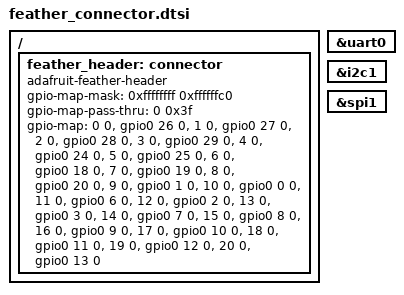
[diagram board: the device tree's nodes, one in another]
/*
 * Copyright (c) 2020 Richard Osterloh <richard.osterloh@gmail.com>
 *
 * SPDX-License-Identifier: Apache-2.0
 */

/ {
	feather_header: connector {
		compatible = "adafruit-feather-header";
		#gpio-cells = <2>;
		gpio-map-mask = <0xffffffff 0xffffffc0>;
		gpio-map-pass-thru = <0 0x3f>;
		gpio-map = <0 0 &gpio0 26 0>,	/* GP26, A0 */
			   <1 0 &gpio0 27 0>,	/* GP27, A1 */
			   <2 0 &gpio0 28 0>,	/* GP28, A2 */
			   <3 0 &gpio0 29 0>,	/* GP29, A3 */
			   <4 0 &gpio0 24 0>,	/* GP24 */
			   <5 0 &gpio0 25 0>,	/* GP25 */
			   <6 0 &gpio0 18 0>,	/* GP18, SCK */
			   <7 0 &gpio0 19 0>,	/* GP19, MOSI */
			   <8 0 &gpio0 20 0>,	/* GP20, MISO */
			   <9 0 &gpio0 1 0>,	/* GP01, RX */
			   <10 0 &gpio0 0 0>,	/* GP00, TX */
			   <11 0 &gpio0 6 0>,	/* GP06, D4 */
			   <12 0 &gpio0 2 0>,	/* GP02, SDA */
			   <13 0 &gpio0 3 0>,	/* GP03, SCL */
			   <14 0 &gpio0 7 0>,	/* GP07, D5 */
			   <15 0 &gpio0 8 0>,	/* GP08, D6 */
			   <16 0 &gpio0 9 0>,	/* GP09 */
			   <17 0 &gpio0 10 0>,	/* GP10 */
			   <18 0 &gpio0 11 0>,	/* GP11 */
			   <19 0 &gpio0 12 0>,	/* GP12 */
			   <20 0 &gpio0 13 0>;	/* GP13 */
	};
};

feather_serial: &uart0 {};

feather_i2c: &i2c1 {};

feather_spi: &spi1 {};
